# CY8C3866AXI_040 register map
File version: 0.1
CY8C38
Registers are 8-bit, read-write, no defined reset value unless marked. A register's access mark holds for its fields unless they carry their own. Offsets are from the block's base; lines under a group give offsets from that group; [hi:lo] are bit positions; {n}, {i} and the like mark numbered series; 'fields as' and 'values as' point back to an identical list; <NAME> marks a mode.

## Memory map
0x00004382 RTC_1 size 0xF — RTC
0x0000642C PWM_FAST size 0x72
0x0000642E PWM_SLOW size 0x72

## RTC_1 — RTC
Base 0x00004382
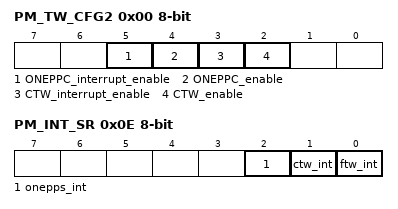
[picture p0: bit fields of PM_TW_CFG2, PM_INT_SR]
0x00 PM_TW_CFG2 — Power timers enable and interrupt enable configuration register
  [5] ONEPPC_interrupt_enable — When set and one pulse-per-second is enabled, an interrupt is issued when the pulse occurs
    1=Enabled (The ONEPPC interrupt is issued. Only if ONEPPC is enabled.); 0=Disabled (No ONEPPC interrupt is issued.)
  [4] ONEPPC_enable
    1=Enabled (The ONEPPC is enabled.); 0=Disabled (The ONEPPC is disabled.)
  [3] CTW_interrupt_enable — An interrupt issue when the CTW reaches the selected interval
    1=Enabled (The CTW interrupt is issued. Only if CTW is enabled.); 0=Disabled (No CTW interrupt is issued.)
  [2] CTW_enable
    1=Enabled (The CTW is enabled.); 0=Disabled (The CTW is disabled.)
0x0E PM_INT_SR — Power Manager Interrupt Status Register
  [2] onepps_int — When set, a onepps event has occured.
  [1] ctw_int — When set, a limited active ready event has occured
  [0] ftw_int — When set, a fast timewheel event has occured

## PWM_SLOW
Base 0x0000642E
0x00 PWM_SLOW_COMPARE_Reg 16-bit — UDB.D0 - Assigned Compare Value
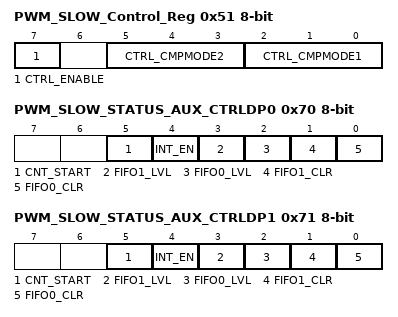
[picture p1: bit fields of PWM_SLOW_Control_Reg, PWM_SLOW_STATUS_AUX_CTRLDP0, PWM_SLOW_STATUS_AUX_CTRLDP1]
0x51 PWM_SLOW_Control_Reg — UDB Control Register - Assigned Control Register Value
  [7] CTRL_ENABLE — Enable the PWM
  [5:3] CTRL_CMPMODE2 — Compare mode 2
  [2:0] CTRL_CMPMODE1 — Compare mode 1
0x70 PWM_SLOW_STATUS_AUX_CTRLDP0 — UDB Auxilliary Control Register
  [5] CNT_START — FIFO0 clear
    0=E_CNT_START0 (Disable counter); 1=E_CNT_START1 (Enable counter)
  [4] INT_EN
    0=E_INT_EN0 (Interrupt disabled); 1=E_INT_EN1 (Interrupt enabled)
  [3] FIFO1_LVL — FIFO level
    0=E_FIFO_LVL_0 (FIFO LVL: input mode: FIFO not full; output mode: FIFO not empty); 1=E_FIFO_LVL_1 (FIFO LVL: input mode: FIFO at least 1/2 empty; output mode: FIFO at least 1/2 full)
  [2] FIFO0_LVL — FIFO level
    values as FIFO1_LVL
  [1] FIFO1_CLR — FIFO1 clear
    0=E_FIFO_CLR_0 (Normal FIFO operation); 1=E_FIFO_CLR_1 (Clear FIFO state)
  [0] FIFO0_CLR — FIFO0 clear
    values as FIFO1_CLR
0x71 PWM_SLOW_STATUS_AUX_CTRLDP1 — UDB Auxilliary Control Register
  fields as PWM_SLOW_STATUS_AUX_CTRLDP0

## PWM_FAST
Base 0x0000642C
Registers as PWM_SLOW (with PWM_SLOW read as PWM_FAST).
